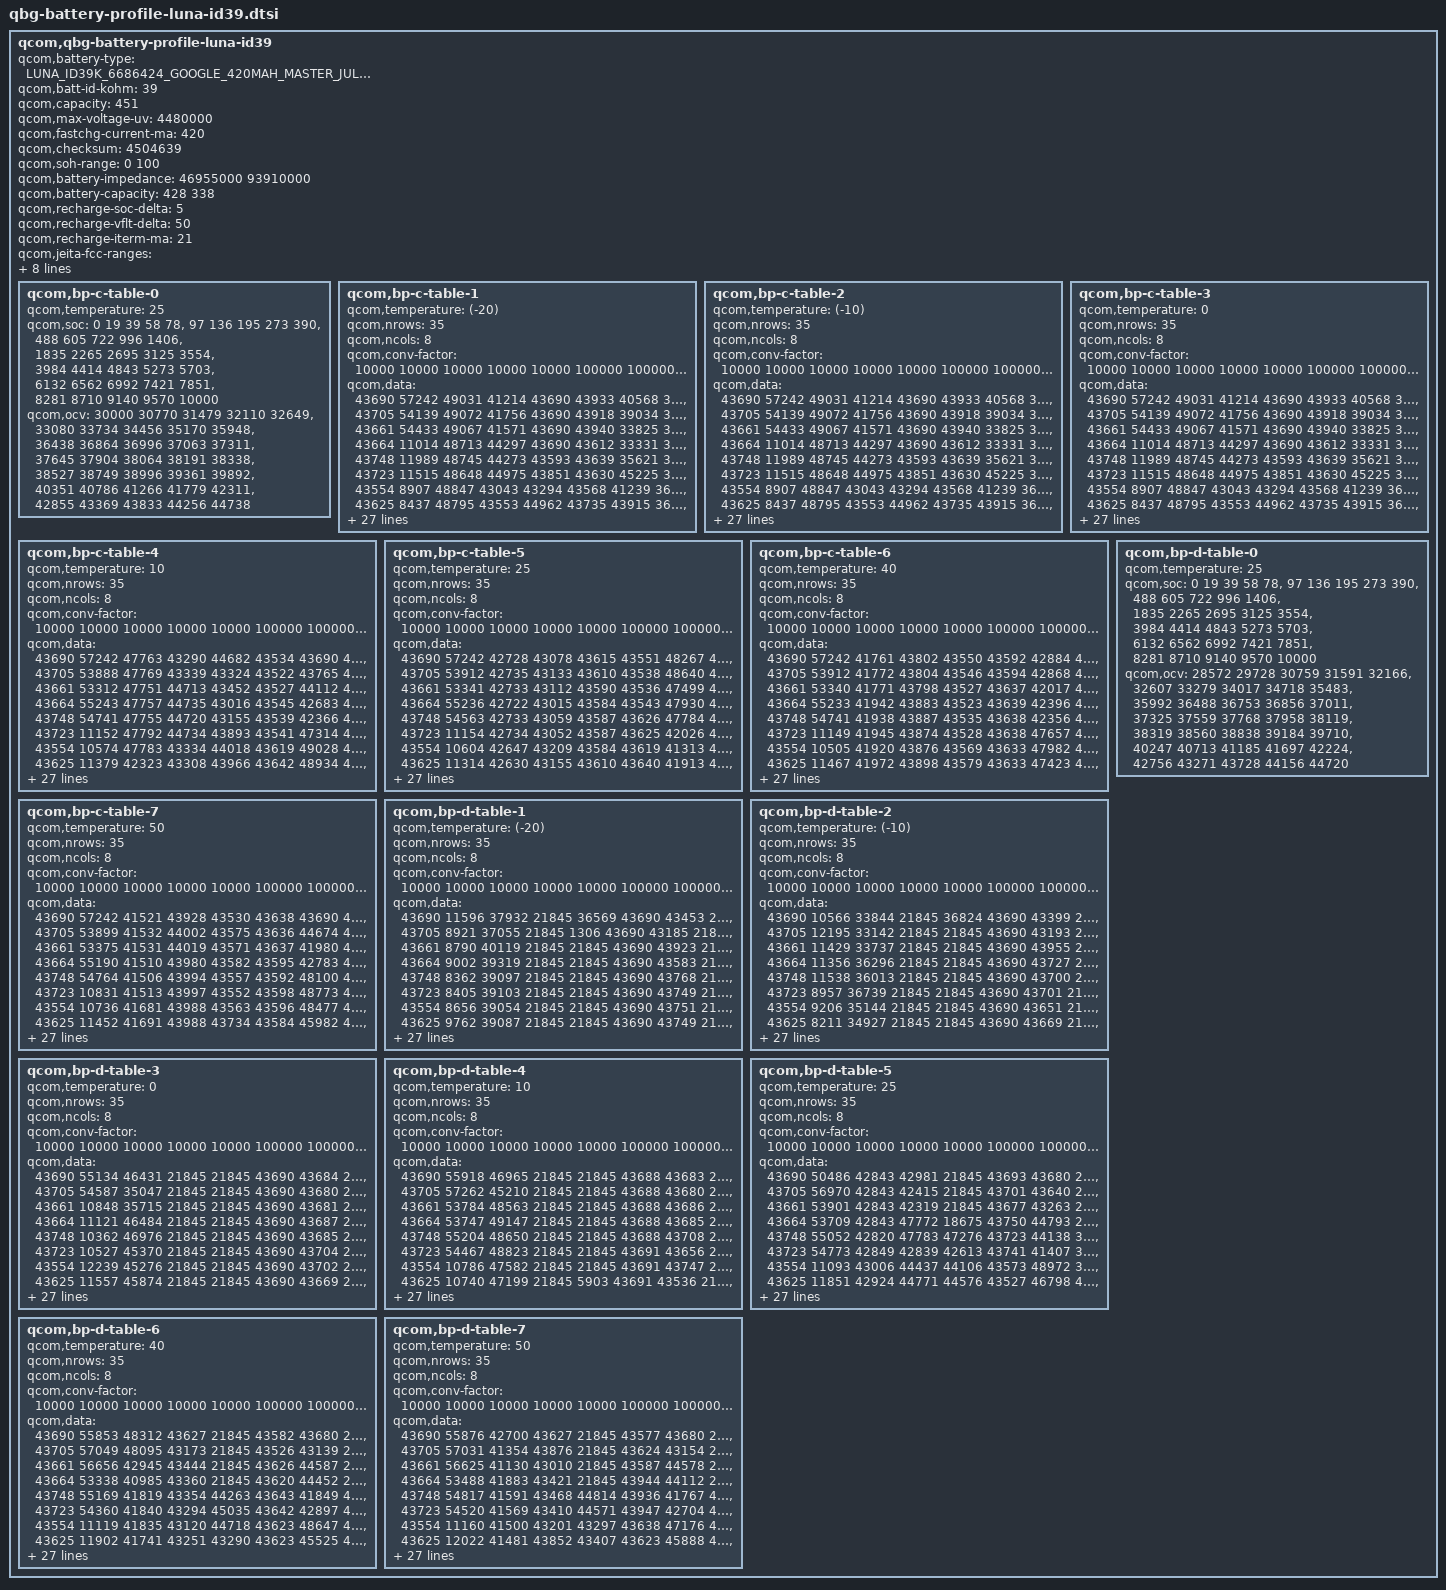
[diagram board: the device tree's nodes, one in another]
/*QBG Profiling Rev. 2.7*/

qcom,qbg-battery-profile-luna-id39 {
	qcom,battery-type = "LUNA_ID39K_6686424_GOOGLE_420MAH_MASTER_JUL11TH2023_ESR_REV7";
	qcom,batt-id-kohm = <39>;
	qcom,capacity = <451>;
	qcom,max-voltage-uv = <4480000>;
	qcom,fastchg-current-ma = <420>;
	qcom,checksum = <4504639>; /*@5, 0.005V, 4% */
	qcom,soh-range = <0 100>;
	/*Nominal_Impedance in 10nohm @ SOC 50% 25C* 0:fresh cell, 1: aged cell*/
	qcom,battery-impedance = <46955000 93910000>;
	/*Nominal_Capacity in mAh. 0: fresh cell, 1:aged cell*/ 
	qcom,battery-capacity = <428 338>;
	/*SOC delta (in percent) dropped from EOC SOC to enable recharge*/ 
	qcom,recharge-soc-delta =<5>;
	/*vfloat delta (in mV) dropped from regular vfloat in recharge*/ 
	qcom,recharge-vflt-delta =<50>;
	/*termination current (in mA) in recharge*/ 
	qcom,recharge-iterm-ma = <21>;

	qcom,jeita-fcc-ranges = <
				0   100 200000
				100 200 275000
				200 420 500000
				420 460 400000>;

	qcom,jeita-fv-ranges = <
				0   100 4480000
				100 200 4480000
				200 420 4480000
				420 460 4480000>;

	/* COOL = 10 DegC, WARM = 42 DegC */
	qcom,jeita-soft-thresholds = <0x2b8a 0x1444>;
	/* COLD = 0 DegC, HOT = 46 DegC */
	qcom,jeita-hard-thresholds = <0x3257 0x1201>;
	/* COOL = 12 DegC, WARM = 44 DegC */
	qcom,jeita-soft-hys-thresholds = <0x2a0b 0x131C>;
	qcom,jeita-soft-fcc-ua = <200000 200000>;
	qcom,jeita-soft-fv-uv = <4200000 4350000>;

	qcom,bp-c-table-0 {
		qcom,temperature = <25>;
		qcom,soc = <    0    19    39    58    78>,
			<   97   136   195   273   390>,
			<  488   605   722   996  1406>,
			< 1835  2265  2695  3125  3554>,
			< 3984  4414  4843  5273  5703>,
			< 6132  6562  6992  7421  7851>,
			< 8281  8710  9140  9570 10000>;
		qcom,ocv = <30000 30770 31479 32110 32649>,
			<33080 33734 34456 35170 35948>,
			<36438 36864 36996 37063 37311>,
			<37645 37904 38064 38191 38338>,
			<38527 38749 38996 39361 39892>,
			<40351 40786 41266 41779 42311>,
			<42855 43369 43833 44256 44738>;
	};
	qcom,bp-c-table-1 {
		qcom,temperature = <(-20)>;
		qcom,nrows = <35>;
		qcom,ncols = <8>;
		qcom,conv-factor = <10000 10000 10000 10000 10000 100000 100000 10000>;
		qcom,data = <43690 57242 49031 41214 43690 43933 40568 33712>,
			<43705 54139 49072 41756 43690 43918 39034 33341>,
			<43661 54433 49067 41571 43690 43940 33825 33465>,
			<43664 11014 48713 44297 43690 43612 33331 36154>,
			<43748 11989 48745 44273 43593 43639 35621 36260>,
			<43723 11515 48648 44975 43851 43630 45225 35896>,
			<43554  8907 48847 43043 43294 43568 41239 36635>,
			<43625  8437 48795 43553 44962 43735 43915 36381>,
			<43963  9943 48781 43755 44671 43558 43954 35155>,
			<43820  9333 48804 43678 44551 43534 43957 35318>,
			<43842 14999 48797 43650 44581 43628 43956 34906>,
			<43255 14869 47451 43667 44594 43524 43956 34840>,
			<43128 14918 47455 43669 44547 43525 43913 34870>,
			<43342 15353 48801 43257 43115 43632 43458 34866>,
			<45012 14548 47456 44240 43789 43550 47471 36405>,
			<44417 14615 47388 44442 43193 43521 48336 36464>,
			<41587 15878 47372 44342 43259 43533 48364 36457>,
			<41005 16260 47590 44400 43052 43535 48921 36373>,
			<42655 16179 47519 41642 43014 43529 48699 36373>,
			<42824 15539 47512 41608 43128 43531 47492 36455>,
			<42298 15386 47520 41702 43431 43573 47230 36784>,
			<48020 15822 47523 41515 43488 43572 48649 36806>,
			<47169 13039 47596 41491 43482 43530 45164 36633>,
			<48691 13127 47542 41478 43008 43573 45549 36458>,
			<48365 12647 47549 41701 43232 43575 47652 35136>,
			<48478 14294 47492 41520 43222 43583 42738 36415>,
			<45832 13703 47566 41905 43087 43556 41190 35995>,
			<45562  2653 47378 41737 43456 43555 41857 33509>,
			<46679  2164 48768 41146 44685 43554 41648 32867>,
			<46081  3656 48640 41196 45047 43555 44088 34635>,
			<35571  3165 49050 41208 44532 43558 44965 39088>,
			<34988   942 48901 41118 41172 43579 44714 40285>,
			<35102    73 48301 41801 42262 43571 43408 59943>,
			<36808  1587 48366 41695 46001 43576 43261 59353>,
			<36282  1254 48336 43898 47303 43759 43538 60423>;
	};
	qcom,bp-c-table-2 {
		qcom,temperature = <(-10)>;
		qcom,nrows = <35>;
		qcom,ncols = <8>;
		qcom,conv-factor = <10000 10000 10000 10000 10000 100000 100000 10000>;
		qcom,data = <43690 57242 49031 41214 43690 43933 40568 33712>,
			<43705 54139 49072 41756 43690 43918 39034 33341>,
			<43661 54433 49067 41571 43690 43940 33825 33465>,
			<43664 11014 48713 44297 43690 43612 33331 36154>,
			<43748 11989 48745 44273 43593 43639 35621 36260>,
			<43723 11515 48648 44975 43851 43630 45225 35896>,
			<43554  8907 48847 43043 43294 43568 41239 36635>,
			<43625  8437 48795 43553 44962 43735 43915 36381>,
			<43963  9943 48781 43755 44671 43558 43954 35155>,
			<43820  9333 48804 43678 44551 43534 43957 35318>,
			<43842 14999 48797 43650 44581 43628 43956 34906>,
			<43255 14869 47451 43667 44594 43524 43956 34840>,
			<43128 14918 47455 43669 44547 43525 43913 34870>,
			<43342 15353 48801 43257 43115 43632 43458 34866>,
			<45012 14548 47456 44240 43789 43550 47471 36405>,
			<44417 14615 47388 44442 43193 43521 48336 36464>,
			<41587 15878 47372 44342 43259 43533 48364 36457>,
			<41005 16260 47590 44400 43052 43535 48921 36373>,
			<42655 16179 47519 41642 43014 43529 48699 36373>,
			<42824 15539 47512 41608 43128 43531 47492 36455>,
			<42298 15386 47520 41702 43431 43573 47230 36784>,
			<48020 15822 47523 41515 43488 43572 48649 36806>,
			<47169 13039 47596 41491 43482 43530 45164 36633>,
			<48691 13127 47542 41478 43008 43573 45549 36458>,
			<48365 12647 47549 41701 43232 43575 47652 35136>,
			<48478 14294 47492 41520 43222 43583 42738 36415>,
			<45832 13703 47566 41905 43087 43556 41190 35995>,
			<45562  2653 47378 41737 43456 43555 41857 33509>,
			<46679  2164 48768 41146 44685 43554 41648 32867>,
			<46081  3656 48640 41196 45047 43555 44088 34635>,
			<35571  3165 49050 41208 44532 43558 44965 39088>,
			<34988   942 48901 41118 41172 43579 44714 40285>,
			<35102    73 48301 41801 42262 43571 43408 59943>,
			<36808  1587 48366 41695 46001 43576 43261 59353>,
			<36282  1254 48336 43898 47303 43759 43538 60423>;
	};
	qcom,bp-c-table-3 {
		qcom,temperature = <0>;
		qcom,nrows = <35>;
		qcom,ncols = <8>;
		qcom,conv-factor = <10000 10000 10000 10000 10000 100000 100000 10000>;
		qcom,data = <43690 57242 49031 41214 43690 43933 40568 33712>,
			<43705 54139 49072 41756 43690 43918 39034 33341>,
			<43661 54433 49067 41571 43690 43940 33825 33465>,
			<43664 11014 48713 44297 43690 43612 33331 36154>,
			<43748 11989 48745 44273 43593 43639 35621 36260>,
			<43723 11515 48648 44975 43851 43630 45225 35896>,
			<43554  8907 48847 43043 43294 43568 41239 36635>,
			<43625  8437 48795 43553 44962 43735 43915 36381>,
			<43963  9943 48781 43755 44671 43558 43954 35155>,
			<43820  9333 48804 43678 44551 43534 43957 35318>,
			<43842 14999 48797 43650 44581 43628 43956 34906>,
			<43255 14869 47451 43667 44594 43524 43956 34840>,
			<43128 14918 47455 43669 44547 43525 43913 34870>,
			<43342 15353 48801 43257 43115 43632 43458 34866>,
			<45012 14548 47456 44240 43789 43550 47471 36405>,
			<44417 14615 47388 44442 43193 43521 48336 36464>,
			<41587 15878 47372 44342 43259 43533 48364 36457>,
			<41005 16260 47590 44400 43052 43535 48921 36373>,
			<42655 16179 47519 41642 43014 43529 48699 36373>,
			<42824 15539 47512 41608 43128 43531 47492 36455>,
			<42298 15386 47520 41702 43431 43573 47230 36784>,
			<48020 15822 47523 41515 43488 43572 48649 36806>,
			<47169 13039 47596 41491 43482 43530 45164 36633>,
			<48691 13127 47542 41478 43008 43573 45549 36458>,
			<48365 12647 47549 41701 43232 43575 47652 35136>,
			<48478 14294 47492 41520 43222 43583 42738 36415>,
			<45832 13703 47566 41905 43087 43556 41190 35995>,
			<45562  2653 47378 41737 43456 43555 41857 33509>,
			<46679  2164 48768 41146 44685 43554 41648 32867>,
			<46081  3656 48640 41196 45047 43555 44088 34635>,
			<35571  3165 49050 41208 44532 43558 44965 39088>,
			<34988   942 48901 41118 41172 43579 44714 40285>,
			<35102    73 48301 41801 42262 43571 43408 59943>,
			<36808  1587 48366 41695 46001 43576 43261 59353>,
			<36282  1254 48336 43898 47303 43759 43538 60423>;
	};
	qcom,bp-c-table-4 {
		qcom,temperature = <10>;
		qcom,nrows = <35>;
		qcom,ncols = <8>;
		qcom,conv-factor = <10000 10000 10000 10000 10000 100000 100000 10000>;
		qcom,data = <43690 57242 47763 43290 44682 43534 43690 46505>,
			<43705 53888 47769 43339 43324 43522 43765 46288>,
			<43661 53312 47751 44713 43452 43527 44112 46938>,
			<43664 55243 47757 44735 43016 43545 42683 47053>,
			<43748 54741 47755 44720 43155 43539 42366 46667>,
			<43723 11152 47792 44734 43893 43541 47314 46795>,
			<43554 10574 47783 43334 44018 43619 49028 45522>,
			<43625 11379 42323 43308 43966 43642 48934 45278>,
			<43963  8981 42353 43040 43776 43622 44861 45832>,
			<43820  9852 42356 43973 43066 43603 43153 45654>,
			<43842  9322 42259 43815 43208 43947 43046 45592>,
			<43255 15080 42366 43824 43157 43939 43032 45814>,
			<43128 14848 42248 43991 43257 43936 43226 45744>,
			<43342 14940 42285 43432 43939 43611 42788 45726>,
			<45012 15188 42438 44566 43835 43549 47289 45945>,
			<44417 14820 42492 44991 43847 43548 47369 45219>,
			<41587 16126 42419 45041 43175 43550 48347 45918>,
			<41005 15950 42066 45016 43144 43544 48270 45942>,
			<42655 16381 42054 44845 43161 43547 48718 45843>,
			<42824 16246 42097 44854 43233 43546 47139 45842>,
			<42298 15405 42109 44857 43055 43524 42199 45924>,
			<48020 15870 42080 44845 43077 43521 42613 45909>,
			<47169 12944 41993 44813 43413 43521 42362 45297>,
			<48691 13102 42044 44919 43402 43524 48271 45305>,
			<48365 12656 42017 44862 43843 43520 42452 45587>,
			<48478 14116 42029 44857 43870 43533 42718 45597>,
			<45832 13806 41987 44908 43171 43529 41258 45989>,
			<45562  2993 42040 44887 43137 43573 41012 45866>,
			<46679  2492 42010 44255 43057 43581 41473 45073>,
			<46081  3970 42079 44137 43519 43581 44426 46789>,
			<35571  3563 42471 44427 44749 43571 44282 46178>,
			<34988   993 42242 44418 44267 43530 44957 35668>,
			<35102   398 42330 44113 41177 43520 43354 36206>,
			<36808  1660 47812 44832 41521 43523 44737 35883>,
			<36282  1083 47836 43047 42217 43560 43931 33116>;
	};
	qcom,bp-c-table-5 {
		qcom,temperature = <25>;
		qcom,nrows = <35>;
		qcom,ncols = <8>;
		qcom,conv-factor = <10000 10000 10000 10000 10000 100000 100000 10000>;
		qcom,data = <43690 57242 42728 43078 43615 43551 48267 47193>,
			<43705 53912 42735 43133 43610 43538 48640 47215>,
			<43661 53341 42733 43112 43590 43536 47499 47164>,
			<43664 55236 42722 43015 43584 43543 47930 47309>,
			<43748 54563 42733 43059 43587 43626 47784 47248>,
			<43723 11154 42734 43052 43587 43625 42026 47268>,
			<43554 10604 42647 43209 43584 43619 41313 47893>,
			<43625 11314 42630 43155 43610 43640 41913 48067>,
			<43963  9160 42669 43194 43950 43637 44522 48015>,
			<43820  9926 42667 43170 43604 43584 44309 47689>,
			<43842  9468 41306 43858 43948 43589 44294 47720>,
			<43255 15018 41340 43840 43615 43610 41719 47831>,
			<43128 14894 41339 43196 43522 43599 42250 47854>,
			<43342 14957 41237 43139 43592 43586 42397 47836>,
			<45012 15125 41224 43109 43827 43618 41072 47934>,
			<44417 14759 41252 43454 43872 43623 42123 47998>,
			<41587 16058 41424 43490 43902 43617 47124 47988>,
			<41005 15898 41466 43489 43796 43619 48832 47881>,
			<42655 16261 41360 43467 43805 43628 48791 47908>,
			<42824 16232 41397 43311 43797 43629 48068 47933>,
			<42298 15573 41376 43513 43143 43629 41147 47894>,
			<48020 15863 41047 43102 43097 43626 44118 47965>,
			<47169 13054 41030 43102 43412 43551 44367 47252>,
			<48691 13163 41086 43497 43109 43548 42518 47956>,
			<48365 12670 41069 43517 43779 43540 42238 47713>,
			<48478 14133 41070 43401 43826 43536 41920 47655>,
			<45832 13816 41067 43492 43782 43536 41598 47714>,
			<45562  2968 40982 43486 43890 43551 44397 48015>,
			<46679  2457 41064 43318 43187 43546 44062 47924>,
			<46081  4077 41060 44712 43160 43546 44491 47262>,
			<35571  3533 41055 44785 43089 43521 44920 47410>,
			<34988   963 41346 44559 44711 43545 45053 49120>,
			<35102   403 41416 44596 44182 43630 44579 48452>,
			<36808  1610 41337 43512 44780 43624 44821 49044>,
			<36282  1128 41320 43831 41550 43950 44028 45586>;
	};
	qcom,bp-c-table-6 {
		qcom,temperature = <40>;
		qcom,nrows = <35>;
		qcom,ncols = <8>;
		qcom,conv-factor = <10000 10000 10000 10000 10000 100000 100000 10000>;
		qcom,data = <43690 57242 41761 43802 43550 43592 42884 42607>,
			<43705 53912 41772 43804 43546 43594 42868 42518>,
			<43661 53340 41771 43798 43527 43637 42017 42526>,
			<43664 55233 41942 43883 43523 43639 42396 42502>,
			<43748 54741 41938 43887 43535 43638 42356 42505>,
			<43723 11149 41945 43874 43528 43638 47657 42545>,
			<43554 10505 41920 43876 43569 43633 47982 42528>,
			<43625 11467 41972 43898 43579 43633 47423 42715>,
			<43963  9141 41978 43875 43564 43596 49012 42725>,
			<43820  9869 41967 43824 43531 43610 42607 42638>,
			<43842  9376 41877 43782 43580 43602 47231 42679>,
			<43255  9570 41886 43909 43616 43952 44309 41318>,
			<43128 15051 41856 43912 43533 43964 41117 41251>,
			<43342 14898 41870 44018 43639 43937 41170 41311>,
			<45012 15315 41917 43791 43996 43600 44393 42623>,
			<44417 14442 41900 43884 43813 43613 41752 42923>,
			<41587 14608 41552 43878 43784 43608 41237 42919>,
			<41005 16090 41539 43875 43983 43590 42779 42513>,
			<42655 16291 41597 43851 43924 43592 42027 42502>,
			<42824 16128 41580 43145 44000 43645 42620 42568>,
			<42298 15558 41501 43137 43824 43594 41504 42988>,
			<48020 15868 41474 43825 43012 43611 44585 42802>,
			<47169 13046 41521 44028 43440 43584 44746 42875>,
			<48691 13179 41529 43887 43231 43637 41079 42793>,
			<48365 12644 41511 43844 44000 43598 42147 42701>,
			<48478 14089 41507 43786 43923 43586 44053 42674>,
			<45832 13809 41517 43886 44016 43633 44285 42699>,
			<45562  2967 41516 43176 43990 43646 44242 42595>,
			<46679  2538 41504 43164 43807 43617 44868 42990>,
			<46081  4093 41528 43043 43894 43630 44237 42874>,
			<35571  3545 41527 43014 43144 43626 44877 42208>,
			<34988   961 41477 43413 43022 43623 44263 42463>,
			<35102   409 41570 43408 43360 43598 44847 47633>,
			<36808  1660 41558 43173 43066 43639 44036 42191>,
			<36282  1151 41495 43889 44904 43964 43195 48023>;
	};
	qcom,bp-c-table-7 {
		qcom,temperature = <50>;
		qcom,nrows = <35>;
		qcom,ncols = <8>;
		qcom,conv-factor = <10000 10000 10000 10000 10000 100000 100000 10000>;
		qcom,data = <43690 57242 41521 43928 43530 43638 43690 41349>,
			<43705 53899 41532 44002 43575 43636 44674 41368>,
			<43661 53375 41531 44019 43571 43637 41980 41369>,
			<43664 55190 41510 43980 43582 43595 42783 41368>,
			<43748 54764 41506 43994 43557 43592 48100 41370>,
			<43723 10831 41513 43997 43552 43598 48773 41351>,
			<43554 10736 41681 43988 43563 43596 48477 41358>,
			<43625 11452 41691 43988 43734 43584 45982 41402>,
			<43963  8829 41677 43977 43733 43591 47293 41027>,
			<43820  8563 41718 44020 43566 43608 47739 41084>,
			<43842 10006 41724 44016 43732 43604 47244 41067>,
			<43255  9684 41723 43957 43559 43916 42977 41006>,
			<43128 14978 41703 43635 43552 43922 41305 41093>,
			<43342 15093 41709 43937 43646 43907 41861 40987>,
			<45012 15257 41623 43994 43928 43967 41966 41433>,
			<44417 14549 41628 44025 44021 43952 41708 41430>,
			<41587 14801 41607 44030 43984 43953 41933 41253>,
			<41005 16108 41608 44009 44011 43961 41084 41367>,
			<42655 15961 41661 44031 43941 43946 42724 41353>,
			<42824 16180 41633 43811 43915 43588 41082 41417>,
			<42298 15566 41643 43901 44007 43609 41577 41334>,
			<48020 15865 44370 43927 43256 43956 44756 42652>,
			<47169 13001 44357 43637 43084 43959 43485 42699>,
			<48691 13172 44354 43934 43245 43951 41751 42663>,
			<48365 12645 44364 43972 43954 43951 42982 41379>,
			<48478 14089 44366 43924 43601 43951 44323 41071>,
			<45832 13813 44360 44016 43913 43613 44240 41381>,
			<45562  3055 44362 43819 44031 43588 44864 41435>,
			<46679  2541 44362 43876 43972 43593 44131 41295>,
			<46081  4042 44366 43840 43801 43632 44867 42746>,
			<35571  3545 44355 43153 43874 43643 44112 42602>,
			<34988   961 44382 43216 43156 43621 44268 42786>,
			<35102   408 41646 43227 43445 43636 44995 42188>,
			<36808  1662 41655 43812 43193 43615 44183 42712>,
			<36282  1139 44397 43647 44204 43914 43778 42463>;
	};
	qcom,bp-d-table-0 {
		qcom,temperature = <25>;
		qcom,soc = <    0    19    39    58    78>,
			<   97   136   195   273   390>,
			<  488   605   722   996  1406>,
			< 1835  2265  2695  3125  3554>,
			< 3984  4414  4843  5273  5703>,
			< 6132  6562  6992  7421  7851>,
			< 8281  8710  9140  9570 10000>;
		qcom,ocv = <28572 29728 30759 31591 32166>,
			<32607 33279 34017 34718 35483>,
			<35992 36488 36753 36856 37011>,
			<37325 37559 37768 37958 38119>,
			<38319 38560 38838 39184 39710>,
			<40247 40713 41185 41697 42224>,
			<42756 43271 43728 44156 44720>;
	};
	qcom,bp-d-table-1 {
		qcom,temperature = <(-20)>;
		qcom,nrows = <35>;
		qcom,ncols = <8>;
		qcom,conv-factor = <10000 10000 10000 10000 10000 100000 100000 10000>;
		qcom,data = <43690 11596 37932 21845 36569 43690 43453 21845>,
			<43705  8921 37055 21845  1306 43690 43185 21845>,
			<43661  8790 40119 21845 21845 43690 43923 21845>,
			<43664  9002 39319 21845 21845 43690 43583 21845>,
			<43748  8362 39097 21845 21845 43690 43768 21845>,
			<43723  8405 39103 21845 21845 43690 43749 21845>,
			<43554  8656 39054 21845 21845 43690 43751 21845>,
			<43625  9762 39087 21845 21845 43690 43749 21845>,
			<43963 10186 34124 21845  9021 43690 43734 21845>,
			<43820  9369 34497 21845 59677 43690 43524 21845>,
			<43842  9320 33078 21845 33638 43690 43913 21845>,
			<43255  9630 32788 21845 45459 43690 43831 21845>,
			<43128  9531 33484 31263 47369 43691 43193 21845>,
			<43342 15081 36048 49380 42719 43691 43438 21845>,
			<45012 15280 36396 38208 40983 43688 44585 31461>,
			<44417 15209 35211 34020 41207 43694 44626   743>,
			<41587 14538 35388 35715 41725 43695 45052  9147>,
			<41005 14421 35520 45654 44052 43693 44819 56880>,
			<42655 14594 46578 48829 44866 43682 44891 52631>,
			<42824 16101 46125 48096 44908 43680 44809 51723>,
			<42298 15958 46172 42260 44807 43681 44832 63428>,
			<48020 16159 46527 42008 44863 43686 44815 61917>,
			<47169 15395 46289 42208 45001 43687 44883 62286>,
			<48691 15676 46155 42229 44619 43684 41677 62032>,
			<48365 13217 46159 42220 44967 43705 41444 62046>,
			<48478 12309 46291 42810 44204 43696 41435 62450>,
			<45832 13910 46277 42883 44269 43574 49093 61529>,
			<45562 13710 46285 42860 44470 43529 49070 63109>,
			<46679  3041 46194 41989 44390 43530 48815 63384>,
			<46081  2496 46130 42248 41615 43581 47199 62650>,
			<35571  4053 46285 47676 41712 43553 47873 62562>,
			<34988  3363 46122 48068 41664 43733 42262 62915>,
			<35102   813 46240 47993 41607 43736 42733 62741>,
			<36808   262 46937 47995 44039 43767 41648 62952>,
			<36282  1138 46239 47982 45026 43753 43498 63342>;
	};
	qcom,bp-d-table-2 {
		qcom,temperature = <(-10)>;
		qcom,nrows = <35>;
		qcom,ncols = <8>;
		qcom,conv-factor = <10000 10000 10000 10000 10000 100000 100000 10000>;
		qcom,data = <43690 10566 33844 21845 36824 43690 43399 21845>,
			<43705 12195 33142 21845 21845 43690 43193 21845>,
			<43661 11429 33737 21845 21845 43690 43955 21845>,
			<43664 11356 36296 21845 21845 43690 43727 21845>,
			<43748 11538 36013 21845 21845 43690 43700 21845>,
			<43723  8957 36739 21845 21845 43690 43701 21845>,
			<43554  9206 35144 21845 21845 43690 43651 21845>,
			<43625  8211 34927 21845 21845 43690 43669 21845>,
			<43963  9968 35671 21845 53038 43690 43732 21845>,
			<43820  9354 35732 21845 35660 43690 43969 21845>,
			<43842  9285 46590 26091 47182 43690 43218 21845>,
			<43255  9672 46278 52293 41027 43691 43457 21845>,
			<43128  9477 47029 37135 44542 43688 44739 26833>,
			<43342 15080 45319 45204 44606 43689 44904 53270>,
			<45012 15281 45949 42217 43473 43692 44522 62189>,
			<44417 15224 45688 42441 43355 43683 41647 63725>,
			<41587 14550 45764 42932 43362 43686 41724 59052>,
			<41005 14735 45771 41231 43271 43706 41531 58032>,
			<42655 14690 45674 41200 43309 43709 41566 61421>,
			<42824 16074 45684 41583 43449 43762 41835 59816>,
			<42298 16298 45576 44383 43114 43582 41197 60298>,
			<48020 16203 45606 41644 43028 43574 42954 60146>,
			<47169 15769 45582 41475 43101 43533 45803 60144>,
			<48691 12810 45645 41576 43336 43524 49107 59914>,
			<48365 12435 45634 41884 44591 43545 47553 59974>,
			<48478 14005 45685 41811 45037 43550 47613 60186>,
			<45832 13460 46057 41025 44186 43527 47121 59518>,
			<45562  2806 45992 41283 44140 43530 48081 59744>,
			<46679  2244 45625 42595 44467 43576 42345 60964>,
			<46081  3794 45764 42785 44440 43567 42191 61336>,
			<35571  3287 45813 42219 44446 43729 42871 61258>,
			<34988   708 45769 42058 44428 43742 42946 60461>,
			<35102   150 45603 42397 44143 43718 41272 60527>,
			<36808  1720 45750 42479 44982 43761 41910 60609>,
			<36282  1138 48631 42377 43467 43756 44213 61438>;
	};
	qcom,bp-d-table-3 {
		qcom,temperature = <0>;
		qcom,nrows = <35>;
		qcom,ncols = <8>;
		qcom,conv-factor = <10000 10000 10000 10000 10000 100000 100000 10000>;
		qcom,data = <43690 55134 46431 21845 21845 43690 43684 21845>,
			<43705 54587 35047 21845 21845 43690 43680 21845>,
			<43661 10848 35715 21845 21845 43690 43681 21845>,
			<43664 11121 46484 21845 21845 43690 43687 21845>,
			<43748 10362 46976 21845 21845 43690 43685 21845>,
			<43723 10527 45370 21845 21845 43690 43704 21845>,
			<43554 12239 45276 21845 21845 43690 43702 21845>,
			<43625 11557 45874 21845 21845 43690 43669 21845>,
			<43963  9074 45764 21845 64465 43690 43534 21845>,
			<43820  9774 45805 26547 47976 43690 43865 21845>,
			<43842  9361 48161 63908 41554 43691 43380 19513>,
			<43255  9624 49012 36393 44839 43688 44870 14803>,
			<43128  9685 49125 48777 43476 43689 44314 49921>,
			<43342  9538 48758 41156 43107 43693 44330 58137>,
			<45012 14967 48757 44327 43202 43687 41540 38480>,
			<44417 15196 47479 41614 43432 43658 42673 37069>,
			<41587 14459 47470 44087 43130 43581 47975 40121>,
			<41005 14838 47577 44266 43010 43528 42387 39133>,
			<42655 14717 47400 44876 43251 43523 42615 34071>,
			<42824 16073 47408 44902 43185 43524 42545 34674>,
			<42298 16263 47366 44886 43181 43544 47247 34722>,
			<48020 15602 47386 44167 43008 43539 45650 34395>,
			<47169 15814 47429 44220 43400 43537 47627 34347>,
			<48691 12903 48774 44068 43486 43627 42319 34518>,
			<48365 12500 47382 44525 43331 43537 47835 34695>,
			<48478 13863 47463 41628 44655 43544 48095 34045>,
			<45832 13335 47374 41918 44809 43533 47654 34062>,
			<45562  2657 47386 41754 44198 43570 42843 39653>,
			<46679  2155 47390 41147 44219 43555 41344 39433>,
			<46081  3691 47370 41181 44890 43563 41182 39511>,
			<35571  3169 47573 41029 44901 43729 40970 39722>,
			<34988   619 47615 41448 44819 43740 41076 39086>,
			<35102    44 47591 41418 44994 43738 41213 39147>,
			<36808  1771 47574 41357 44705 43721 41737 39709>,
			<36282  1124 47380 41009 43066 43768 41581 39458>;
	};
	qcom,bp-d-table-4 {
		qcom,temperature = <10>;
		qcom,nrows = <35>;
		qcom,ncols = <8>;
		qcom,conv-factor = <10000 10000 10000 10000 10000 100000 100000 10000>;
		qcom,data = <43690 55918 46965 21845 21845 43688 43683 21845>,
			<43705 57262 45210 21845 21845 43688 43680 21845>,
			<43661 53784 48563 21845 21845 43688 43686 21845>,
			<43664 53747 49147 21845 21845 43688 43685 21845>,
			<43748 55204 48650 21845 21845 43688 43708 21845>,
			<43723 54467 48823 21845 21845 43691 43656 21845>,
			<43554 10786 47582 21845 21845 43691 43747 21845>,
			<43625 10740 47199 21845  5903 43691 43536 21845>,
			<43963 11471 47307 29636 36156 43690 43854 21845>,
			<43820  9034 48092 39087 41493 43691 44661   180>,
			<43842  9867 47710 47345 43359 43689 41679 52340>,
			<43255  9371 47830 41848 43131 43693 41349 61155>,
			<43128  9617 47871 44376 43105 43685 41139 37791>,
			<43342  9578 47821 44576 43899 43771 41210 34336>,
			<45012 15061 47851 43264 43968 43568 42745 36560>,
			<44417 15206 42334 44753 43861 43525 42356 35118>,
			<41587 14432 42290 44606 43223 43626 48021 35617>,
			<41005 14832 42242 44748 43202 43630 41990 46534>,
			<42655 14711 42244 44795 43193 43628 42376 46941>,
			<42824 15881 42260 44586 43172 43617 48328 47048>,
			<42298 16337 42286 44742 43253 43623 47139 47017>,
			<48020 15554 42280 44584 43218 43621 42280 46597>,
			<47169 15662 42291 44561 43221 43616 42176 46810>,
			<48691 12878 42291 44961 43013 43625 41994 46605>,
			<48365 12341 42276 45020 43393 43542 42483 47098>,
			<48478 13914 42453 44234 44793 43626 47586 46566>,
			<45832 13737 42487 44046 44974 43548 47786 35480>,
			<45562  2676 42440 44086 44989 43535 41130 35583>,
			<46679  2149 42442 44034 44975 43582 41641 35549>,
			<46081  3697 42471 44112 44566 43556 44362 35430>,
			<35571  3142 42495 44516 44748 43576 41550 35820>,
			<34988   577 42436 44502 44774 43556 41821 35648>,
			<35102    24 42443 44328 44680 43558 41193 34964>,
			<36808  1777 42437 44417 43500 43563 41767 34954>,
			<36282  1134 42290 44131 43261 43742 41637 35798>;
	};
	qcom,bp-d-table-5 {
		qcom,temperature = <25>;
		qcom,nrows = <35>;
		qcom,ncols = <8>;
		qcom,conv-factor = <10000 10000 10000 10000 10000 100000 100000 10000>;
		qcom,data = <43690 50486 42843 42981 21845 43693 43680 21845>,
			<43705 56970 42843 42415 21845 43701 43640 21845>,
			<43661 53901 42843 42319 21845 43677 43263 21845>,
			<43664 53709 42843 47772 18675 43750 44793 21845>,
			<43748 55052 42820 47783 47276 43723 44138 38876>,
			<43723 54773 42849 42839 42613 43741 41407 39699>,
			<43554 11093 43006 44437 44106 43573 48972 36516>,
			<43625 11851 42924 44771 44576 43527 46798 46255>,
			<43963 11572 42567 43365 43485 43547 46144 45444>,
			<43820  8241 42569 43310 43139 43541 46349 45782>,
			<43842  9778 42604 43408 43817 43618 45393 48176>,
			<43255  9250 42529 43434 43997 43618 42166 49101>,
			<43128  9531 42535 43441 43827 43641 41317 49035>,
			<43342  9554 42725 43221 43958 43543 42134 47547>,
			<45012 14905 42634 43148 43608 43593 42102 47899>,
			<44417 15207 42669 43052 43822 43634 41235 47253>,
			<41587 14365 41324 43017 43890 43596 42547 47232>,
			<41005 14626 41240 43117 43159 43608 42035 47351>,
			<42655 16108 41230 43117 43051 43608 41987 47326>,
			<42824 15949 41274 43056 43204 43596 41018 47942>,
			<42298 16133 41439 43039 43190 43593 41164 47906>,
			<48020 15370 41464 43128 43902 43639 42673 48029>,
			<47169 15644 41365 43113 43799 43645 41253 47685>,
			<48691 13242 41375 43133 43900 43643 42715 48032>,
			<48365 12724 41345 43296 43062 43610 48175 47325>,
			<48478 14237 41406 43302 43375 43637 47651 47422>,
			<45832 13731 41403 43515 43343 43619 41493 47401>,
			<45562  2635 41402 43513 43314 43616 44109 47517>,
			<46679  2123 41402 43374 43105 43644 44381 47529>,
			<46081  3674 41355 44706 43159 43641 41970 47205>,
			<35571  3502 41375 43383 43146 43624 41882 47130>,
			<34988   941 41455 43364 43170 43627 41034 47108>,
			<35102   122 41434 43479 43148 43626 41186 47124>,
			<36808  1750 41272 43490 43184 43542 41006 47125>,
			<36282  1050 41220 43395 43890 43538 41314 47126>;
	};
	qcom,bp-d-table-6 {
		qcom,temperature = <40>;
		qcom,nrows = <35>;
		qcom,ncols = <8>;
		qcom,conv-factor = <10000 10000 10000 10000 10000 100000 100000 10000>;
		qcom,data = <43690 55853 48312 43627 21845 43582 43680 21845>,
			<43705 57049 48095 43173 21845 43526 43139 21845>,
			<43661 56656 42945 43444 21845 43626 44587 21845>,
			<43664 53338 40985 43360 21845 43620 44452 21845>,
			<43748 55169 41819 43354 44263 43643 41849 49118>,
			<43723 54360 41840 43294 45035 43642 42897 47369>,
			<43554 11119 41835 43120 44718 43623 48647 47912>,
			<43625 11902 41741 43251 43290 43623 45525 47629>,
			<43963 11572 41786 43166 43297 43621 35468 47746>,
			<43820  8445 41770 43150 43156 43646 35043 42010>,
			<43842  9861 41924 43198 44009 43633 35532 42787>,
			<43255  9358 41975 43865 43623 43593 49061 42621>,
			<43128  9515 41975 43239 43912 43635 42855 42791>,
			<43342  9555 41979 43849 43539 43596 47907 42551>,
			<45012 15041 41885 44025 43550 43965 42282 41341>,
			<44417 15112 41906 43804 43906 43942 42620 42557>,
			<41587 14380 41899 43783 44001 43961 42715 42544>,
			<41005 14807 41564 43831 43174 43966 41806 42986>,
			<42655 16118 41539 43850 43234 43925 41746 42758>,
			<42824 16292 41585 43175 43866 44000 41449 42961>,
			<42298 16246 41575 43852 43900 43940 41198 42895>,
			<48020 15471 41578 43894 43995 43950 41390 42502>,
			<47169 15741 41503 43897 43916 43606 42866 42746>,
			<48691 13190 41473 43882 44027 43609 42776 42703>,
			<48365 12784 41481 43198 43036 43943 47778 42117>,
			<48478 14233 41521 43850 43506 43614 41898 42197>,
			<45832 13400 41521 43163 43121 43964 44432 42190>,
			<45562  2661 41524 43124 43884 43918 41795 42162>,
			<46679  2147 41480 43077 44019 43606 41019 42771>,
			<46081  3697 41473 43010 43933 43640 41198 42954>,
			<35571  3163 41491 43207 43957 43629 41444 42928>,
			<34988   580 41568 43138 43958 43621 41421 42568>,
			<35102    22 41599 43852 43908 43635 41036 42520>,
			<36808  1754 41536 43900 44012 43591 42514 42606>,
			<36282  1080 41900 43860 43977 43948 42456 42883>;
	};
	qcom,bp-d-table-7 {
		qcom,temperature = <50>;
		qcom,nrows = <35>;
		qcom,ncols = <8>;
		qcom,conv-factor = <10000 10000 10000 10000 10000 100000 100000 10000>;
		qcom,data = <43690 55876 42700 43627 21845 43577 43680 21845>,
			<43705 57031 41354 43876 21845 43624 43154 21845>,
			<43661 56625 41130 43010 21845 43587 44578 21845>,
			<43664 53488 41883 43421 21845 43944 44112 21845>,
			<43748 54817 41591 43468 44814 43936 41767 47544>,
			<43723 54520 41569 43410 44571 43947 42704 48075>,
			<43554 11160 41500 43201 43297 43638 47176 42480>,
			<43625 12022 41481 43852 43407 43623 45888 42192>,
			<43963 11745 41528 43875 43439 43634 46436 42164>,
			<43820  8331 41683 43796 43207 43638 35259 42995>,
			<43842  8515 41668 43781 44024 43598 35223 42678>,
			<43255 10111 41672 43825 43631 43587 45185 41423>,
			<43128  9705 41719 43898 43936 43592 42655 41292>,
			<43342  9573 41727 43835 43545 43584 42753 41450>,
			<45012 14998 41698 43949 43572 43933 42297 41178>,
			<44417 15326 41629 43979 43946 43918 42983 41350>,
			<41587 14579 41602 44013 43910 43911 41386 41357>,
			<41005 14838 41610 43978 43830 44009 41039 41222>,
			<42655 16077 41648 43800 43194 43983 40970 42690>,
			<42824 16258 41658 43828 43197 44020 41890 42740>,
			<42298 16199 41644 43883 43820 43971 41186 41283>,
			<48020 15480 44373 43828 43911 43959 41083 41461>,
			<47169 15689 44381 43972 43600 43964 42567 41054>,
			<48691 13203 44379 44019 43957 43914 42992 41379>,
			<48365 12798 44352 43992 43063 43961 41025 42549>,
			<48478 14234 44354 43901 43067 43970 41680 42581>,
			<45832 13377 44364 43047 43828 43971 41053 42621>,
			<45562  2659 44354 43021 43916 43955 42624 42705>,
			<46679  2156 44358 43204 43602 43594 42599 42677>,
			<46081  3709 44357 43155 43617 43641 47791 41321>,
			<35571  3136 44382 43857 43539 43647 47907 41435>,
			<34988   590 44374 43795 43539 43593 47918 41368>,
			<35102    27 41635 43988 43621 43606 42240 41381>,
			<36808  1736 41660 44027 43960 43942 41323 41354>,
			<36282  1236 41615 43934 43979 43960 44104 41430>;
	};
};
